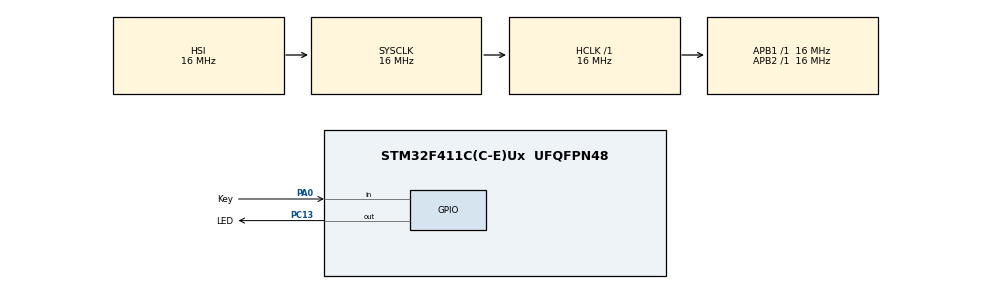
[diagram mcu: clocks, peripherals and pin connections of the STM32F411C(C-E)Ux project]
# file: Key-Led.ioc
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Mcu.Family=STM32F4
Mcu.Name=STM32F411C(C-E)Ux
Mcu.Package=UFQFPN48
NVIC.PriorityGroup=NVIC_PRIORITYGROUP_4
PA0-WKUP.GPIO_Label=Key
PA0-WKUP.GPIO_PuPd=GPIO_PULLUP
PA0-WKUP.Signal=GPIO_Input
PA13.Mode=Serial_Wire
PA13.Signal=SYS_JTMS-SWDIO
PA14.Mode=Serial_Wire
PA14.Signal=SYS_JTCK-SWCLK
PC13-ANTI_TAMP.GPIO_Label=LED
PC13-ANTI_TAMP.Signal=GPIO_Output
PC14-OSC32_IN.Mode=LSE-External-Oscillator
PC14-OSC32_IN.Signal=RCC_OSC32_IN
PC15-OSC32_OUT.Mode=LSE-External-Oscillator
PC15-OSC32_OUT.Signal=RCC_OSC32_OUT
PH0\ -\ OSC_IN.Mode=HSE-External-Oscillator
PH0\ -\ OSC_IN.Signal=RCC_OSC_IN
PH1\ -\ OSC_OUT.Mode=HSE-External-Oscillator
PH1\ -\ OSC_OUT.Signal=RCC_OSC_OUT
ProjectManager.HeapSize=0x200
ProjectManager.StackSize=0x400
ProjectManager.TargetToolchain=MDK-ARM V5
RCC.AHBFreq_Value=16000000
RCC.APB1Freq_Value=16000000
RCC.APB2Freq_Value=16000000
RCC.CortexFreq_Value=16000000
RCC.HSE_VALUE=25000000
RCC.HSI_VALUE=16000000
RCC.SYSCLKFreq_VALUE=16000000
RCC.VCOOutputFreq_Value=192000000
board=custom

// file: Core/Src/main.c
/* USER CODE BEGIN Header */
/**
  ******************************************************************************
  * @file           : main.c
  * @brief          : Main program body
  ******************************************************************************
  * @attention
  *
  * Copyright (c) 2026 STMicroelectronics.
  * All rights reserved.
  *
  * This software is licensed under terms that can be found in the LICENSE file
  * in the root directory of this software component.
  * If no LICENSE file comes with this software, it is provided AS-IS.
  *
  ******************************************************************************
  */
/* USER CODE END Header */
#include "main.h"
#include "gpio.h"

#include "LedState.h"

void SystemClock_Config(void);

int main(void)
{

  /* MCU Configuration--------------------------------------------------------*/

  /* Reset of all peripherals, Initializes the Flash interface and the Systick. */
  HAL_Init();

  /* Configure the system clock */
  SystemClock_Config();

  /* Initialize all configured peripherals */
  MX_GPIO_Init();

  /* Infinite loop */
  /* USER CODE BEGIN WHILE */

  // 直接声明结构体变量
  LedStatus led = {
      .GPIO_Port = LED_GPIO_Port,
      .GPIO_Pin  = LED_Pin
  };
  KeyStatus key = {
      .GPIO_Port = Key_GPIO_Port,
      .GPIO_Pin  = Key_Pin

  };

 static volatile KeyState KeyCurrentState = KEY_Idle ;

//  static volatile KeyEvent KeyCurrentEvent = KEY_Event_Idle ;

  while (1)
  {
    /* USER CODE END WHILE */

    // if(GetKeyState(&key) == KEY_Pressed)
    // // if(HAL_GPIO_ReadPin(Key_GPIO_Port, Key_Pin) == GPIO_PIN_RESET)
    // {
    //   // HAL_GPIO_WritePin(LED_GPIO_Port, LED_Pin, GPIO_PIN_SET);
    //   HAL_Delay(10);
    //   HAL_GPIO_TogglePin(LED_GPIO_Port, LED_Pin);
    //   if( HAL_GPIO_ReadPin(Key_GPIO_Port, Key_Pin) == GPIO_PIN_RESET )
    //     while(HAL_GPIO_ReadPin(Key_GPIO_Port, Key_Pin) == GPIO_PIN_RESET){}
    // }

    switch ( KeyCurrentState  )
    {
        case KEY_Idle :
            if (GetKeyState(&key) == KEY_Pressed )
            {
                KeyCurrentState = KEY_Pressed ;
            }
            break;

        case KEY_Debounce :
            HAL_Delay(10);
            KeyCurrentState = KEY_Released ;
            break;

        case KEY_Pressed :

            KeyCurrentState = KEY_Debounce ;
            break;

        case KEY_Released :
            {
                // HAL_GPIO_TogglePin(LED_GPIO_Port, LED_Pin);        // 当前状态机 流转有问题，流转到这里会持续进入，持续翻转
                if( HAL_GPIO_ReadPin(Key_GPIO_Port, Key_Pin) == GPIO_PIN_SET )      // 检测到上升沿 才进行翻转  状态函数有问题，参数类型不对
                {
                    HAL_GPIO_TogglePin(LED_GPIO_Port, LED_Pin); // 翻转 动作转移到这里，后置，松手翻转。无问题
                    KeyCurrentState =  KEY_Idle;
                }
            }
            break;

        default:
            break ;
    }

  }
}

void SystemClock_Config(void)
{
  RCC_OscInitTypeDef RCC_OscInitStruct = {0};
  RCC_ClkInitTypeDef RCC_ClkInitStruct = {0};

  /** Configure the main internal regulator output voltage
  */
  __HAL_RCC_PWR_CLK_ENABLE();
  __HAL_PWR_VOLTAGESCALING_CONFIG(PWR_REGULATOR_VOLTAGE_SCALE1);

  /** Initializes the RCC Oscillators according to the specified parameters
  * in the RCC_OscInitTypeDef structure.
  */
  RCC_OscInitStruct.OscillatorType = RCC_OSCILLATORTYPE_HSI;
  RCC_OscInitStruct.HSIState = RCC_HSI_ON;
  RCC_OscInitStruct.HSICalibrationValue = RCC_HSICALIBRATION_DEFAULT;
  RCC_OscInitStruct.PLL.PLLState = RCC_PLL_NONE;
  if (HAL_RCC_OscConfig(&RCC_OscInitStruct) != HAL_OK)
  {
    Error_Handler();
  }

  /** Initializes the CPU, AHB and APB buses clocks
  */
  RCC_ClkInitStruct.ClockType = RCC_CLOCKTYPE_HCLK|RCC_CLOCKTYPE_SYSCLK
                              |RCC_CLOCKTYPE_PCLK1|RCC_CLOCKTYPE_PCLK2;
  RCC_ClkInitStruct.SYSCLKSource = RCC_SYSCLKSOURCE_HSI;
  RCC_ClkInitStruct.AHBCLKDivider = RCC_SYSCLK_DIV1;
  RCC_ClkInitStruct.APB1CLKDivider = RCC_HCLK_DIV1;
  RCC_ClkInitStruct.APB2CLKDivider = RCC_HCLK_DIV1;

  if (HAL_RCC_ClockConfig(&RCC_ClkInitStruct, FLASH_LATENCY_0) != HAL_OK)
  {
    Error_Handler();
  }
}

void Error_Handler(void)
{
  __disable_irq();
  while (1)
  {
  }
}
